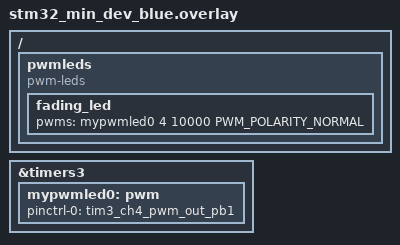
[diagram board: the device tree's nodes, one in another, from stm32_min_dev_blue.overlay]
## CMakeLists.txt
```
# SPDX-License-Identifier: Apache-2.0

cmake_minimum_required(VERSION 3.20.0)
find_package(Zephyr REQUIRED HINTS $ENV{ZEPHYR_BASE})
project(zephyr_my_project)

target_sources(app PRIVATE src/main.c)
```

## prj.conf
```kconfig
CONFIG_GPIO=y
CONFIG_PRINTK=y
CONFIG_PWM=y
```

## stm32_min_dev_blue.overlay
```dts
//For the LED
// / {
//     leds {
//         compatible = "gpio-leds";
//         blinking_led: blinking_led {
//             gpios = <&gpioc 13 GPIO_ACTIVE_HIGH>; #pin PC13
//             #gpios = <&gpioa 11 GPIO_ACTIVE_HIGH>; #pin PA11
//         };
//     };
// };

// For the PWM
&timers3
{   
    status = "okay"; //Enable timer3
    mypwmled0: pwm {
        status = "okay"; //enable pwm
        pinctrl-0 = <&tim3_ch4_pwm_out_pb1>;
        pinctrl-names = "default";
    };
};

/ {
    pwmleds {
        compatible = "pwm-leds";
        fading_led: fading_led {
            pwms = <&mypwmled0 4 10000 PWM_POLARITY_NORMAL>;
        };
    };
};
```

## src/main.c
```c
#include <zephyr/device.h>
#include <zephyr/drivers/pwm.h>
#include <zephyr/sys/printk.h>
#include <zephyr/kernel.h>

#define NUM_STEPS 100U
#define SLEEP_DELTA_MSEC 20U

static uint32_t pulse_width_nsec = 0U;
static uint32_t pulse_width_delta_nsec = 0U;
static uint32_t steps_taken = 0U;
static bool increasing_intensity = true;

static const struct pwm_dt_spec fading_led = PWM_DT_SPEC_GET(DT_NODELABEL(fading_led));

void led_delta_timer_handler(struct k_timer *timer_info)
{
    int ret;
    if (increasing_intensity) {
        if (steps_taken < NUM_STEPS) {
            ret = pwm_set_pulse_dt(&fading_led, pulse_width_nsec);
            steps_taken++;
            pulse_width_nsec += pulse_width_delta_nsec;
        } else {
            increasing_intensity = false;
            steps_taken--;
            pulse_width_nsec -= pulse_width_delta_nsec;
        }
    } else {
        if (steps_taken > 0) {
            ret = pwm_set_pulse_dt(&fading_led, pulse_width_nsec);
            steps_taken--;
            pulse_width_nsec -= pulse_width_delta_nsec;
        } else {
            increasing_intensity = true;
            steps_taken++;
            pulse_width_nsec += pulse_width_delta_nsec;
        }
    }
}

K_TIMER_DEFINE(led_delta_timer, led_delta_timer_handler, NULL);


void main(void)
{
    if (!device_is_ready(fading_led.dev)) {
        printk("Error: PWM device %s is not ready\n", fading_led.dev->name);
        return;
    }

    // int ret;
    // while (1) {
    //     ret = pwm_set_pulse_dt(&fading_led, 0);
    //     k_sleep(K_SECONDS(1));
    //     ret = pwm_set_pulse_dt(&fading_led, 5000);
    //     k_sleep(K_SECONDS(1));
    //     ret = pwm_set_pulse_dt(&fading_led, 10000);
    //     k_sleep(K_SECONDS(1));
    //     ret = pwm_set_pulse_dt(&fading_led, 5000);
    //     k_sleep(K_SECONDS(1));
    // }
    pulse_width_delta_nsec = fading_led.period / NUM_STEPS;

    k_timer_start(&led_delta_timer, K_MSEC(SLEEP_DELTA_MSEC), K_MSEC(SLEEP_DELTA_MSEC) ); 
}
```

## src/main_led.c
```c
#include <zephyr/device.h>
#include <zephyr/drivers/gpio.h>
#include <zephyr/kernel.h>

// static const struct device *gpio_ct_dev = DEVICE_DT_GET(DT_NODELABEL(gpioc));
// Anstracted away in stm32_min_dev_blue.overlay
static const struct gpio_dt_spec led = GPIO_DT_SPEC_GET(DT_NODELABEL(blinking_led),gpios);

void main(void)
{
	if(!device_is_ready(led.port)) {
		return;
	}

	int ret;
	// ret = gpio_pin_configure(gpio_ct_dev, 13, GPIO_OUTPUT_ACTIVE);
	// Anstracted away in stm32_min_dev_blue.overlay
	ret = gpio_pin_configure_dt(&led, GPIO_OUTPUT_ACTIVE);
	if (ret != 0) {
		return;
	}
	while(true) {
		// ret = gpio_pin_set_raw(gpio_ct_dev, 13, 1);
		// Anstracted away in stm32_min_dev_blue.overlay
		ret = gpio_pin_toggle_dt(&led);
		if (ret !=0) {
			return;
		}
		k_msleep(1000);
	}
}
```
